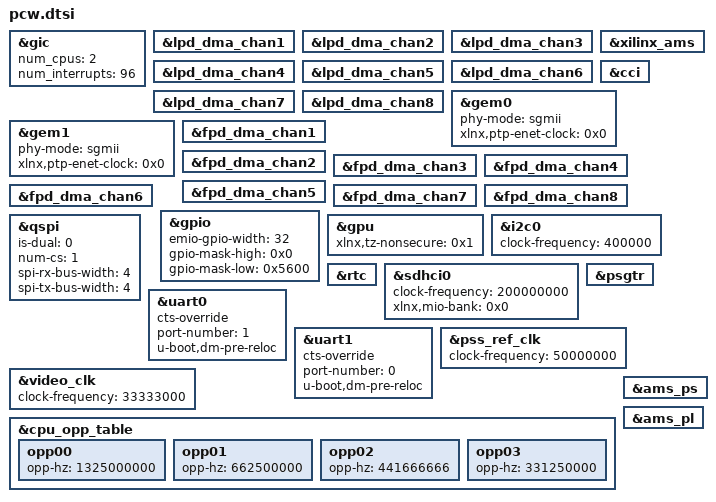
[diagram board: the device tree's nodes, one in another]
/*
 * CAUTION: This file is automatically generated by Xilinx.
 * Version:  
 * Today is: Thu Mar 30 06:41:39 2023
 */


&gic {
	num_cpus = <2>;
	num_interrupts = <96>;
};
&lpd_dma_chan1 {
	status = "okay";
};
&lpd_dma_chan2 {
	status = "okay";
};
&lpd_dma_chan3 {
	status = "okay";
};
&lpd_dma_chan4 {
	status = "okay";
};
&lpd_dma_chan5 {
	status = "okay";
};
&lpd_dma_chan6 {
	status = "okay";
};
&lpd_dma_chan7 {
	status = "okay";
};
&lpd_dma_chan8 {
	status = "okay";
};
&xilinx_ams {
	status = "okay";
};
&cci {
	status = "okay";
};
&gem0 {
	phy-mode = "sgmii";
	status = "okay";
	xlnx,ptp-enet-clock = <0x0>;
};
&gem1 {
	phy-mode = "sgmii";
	status = "okay";
	xlnx,ptp-enet-clock = <0x0>;
};
&fpd_dma_chan1 {
	status = "okay";
};
&fpd_dma_chan2 {
	status = "okay";
};
&fpd_dma_chan3 {
	status = "okay";
};
&fpd_dma_chan4 {
	status = "okay";
};
&fpd_dma_chan5 {
	status = "okay";
};
&fpd_dma_chan6 {
	status = "okay";
};
&fpd_dma_chan7 {
	status = "okay";
};
&fpd_dma_chan8 {
	status = "okay";
};
&gpio {
	emio-gpio-width = <32>;
	gpio-mask-high = <0x0>;
	gpio-mask-low = <0x5600>;
	status = "okay";
};
&gpu {
	status = "okay";
	xlnx,tz-nonsecure = <0x1>;
};
&i2c0 {
	clock-frequency = <400000>;
	status = "okay";
};
&qspi {
	is-dual = <0>;
	num-cs = <1>;
	spi-rx-bus-width = <4>;
	spi-tx-bus-width = <4>;
	status = "okay";
};
&rtc {
	status = "okay";
};
&sdhci0 {
	clock-frequency = <200000000>;
	status = "okay";
	xlnx,mio-bank = <0x0>;
};
&psgtr {
	status = "okay";
};
&uart0 {
	cts-override ;
	device_type = "serial";
	port-number = <1>;
	status = "okay";
	u-boot,dm-pre-reloc ;
};
&uart1 {
	cts-override ;
	device_type = "serial";
	port-number = <0>;
	status = "okay";
	u-boot,dm-pre-reloc ;
};
&pss_ref_clk {
	clock-frequency = <50000000>;
};
&video_clk {
	clock-frequency = <33333000>;
};
&cpu_opp_table {
	opp00 {
		opp-hz = /bits/ 64 <1325000000>;
	};
	opp01 {
		opp-hz = /bits/ 64 <662500000>;
	};
	opp02 {
		opp-hz = /bits/ 64 <441666666>;
	};
	opp03 {
		opp-hz = /bits/ 64 <331250000>;
	};
};
&ams_ps {
	status = "okay";
};
&ams_pl {
	status = "okay";
};
